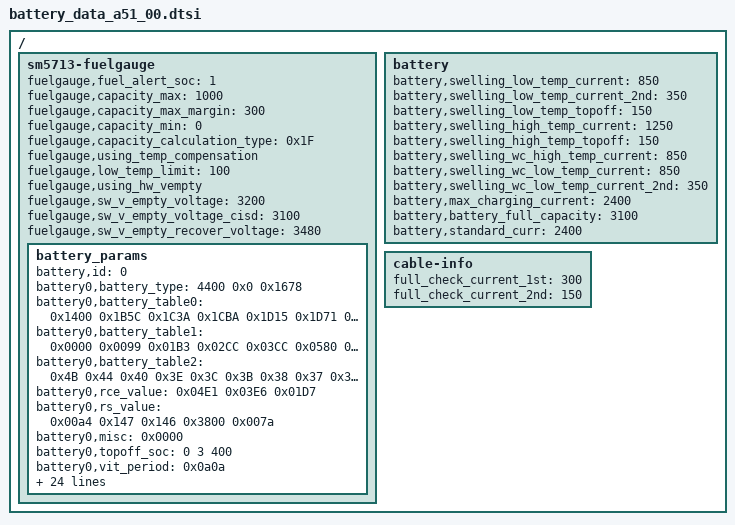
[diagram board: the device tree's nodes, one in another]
/*
 * Vogue battery device tree common
 *
 * Copyright (c) 2018 Samsung Electronics Co., Ltd.
 *		http://www.samsung.com
 *
 * This program is free software; you can redistribute it and/or modify
 * it under the terms of the GNU General Public License version 2 as
 * published by the Free Software Foundation.
 */

#include "battery_data_a51_common.dtsi"

/ {
	fragment@battery {
		target-path = "/";
		__overlay__ {
			sm5713-fuelgauge {
				status = "okay";
				fuelgauge,fuel_alert_soc = <1>;
				fuelgauge,capacity_max = <1000>;
				fuelgauge,capacity_max_margin = <300>;
				fuelgauge,capacity_min = <0>;
				fuelgauge,capacity_calculation_type = <0x1F>;
				fuelgauge,using_temp_compensation;
				fuelgauge,low_temp_limit = <100>;
				fuelgauge,using_hw_vempty;
				fuelgauge,sw_v_empty_voltage = <3200>;
				fuelgauge,sw_v_empty_voltage_cisd = <3100>;
				fuelgauge,sw_v_empty_recover_voltage = <3480>;
				battery_params {
					battery,id = <0>;
					battery0,battery_type = <4400 0x0 0x1678>; /* batt_v_max, min_cap, cap */
					battery0,battery_table0 = <
						0x1400 0x1B5C 0x1C3A 0x1CBA 0x1D15 0x1D71 0x1D85 0x1D8B
						0x1DE2 0x1E07 0x1E3A 0x1E5D 0x1E7B 0x1EA2 0x1ED6 0x1EFD
						0x1F69 0x1FB2 0x1FDF 0x2018 0x2078 0x20C3 0x21F2 0x2400
						>;
					battery0,battery_table1 = <
						0x0000 0x0099 0x01B3 0x02CC 0x03CC 0x0580 0x0819 0x0ACC
						0x12CC 0x1819 0x2033 0x2833 0x2D80 0x32E6 0x3833 0x3AE6
						0x4033 0x4599 0x4AE6 0x4D99 0x5033 0x5599 0x6400 0x6419
						>;
					battery0,battery_table2 = <
						0x4B 0x44 0x40 0x3E 0x3C 0x3B 0x38 0x37
						0x35 0x34 0x34 0x33 0x33 0x33 0x33 0x32
						>;
					battery0,rce_value = <0x04E1 0x03E6 0x01D7>;
					battery0,rs_value = <0x00a4 0x147 0x146 0x3800 0x007a>; /*rs p_mix_factor, n_mix_factor max min*/
					battery0,misc = <0x0000>;
					battery0,topoff_soc = <0 3 400>; /*disable soc*/
					battery0,vit_period = <0x0a0a>;
					battery0,dtcd_value = <0x1>;
					battery0,volt_cal = <0x8012 0x8012>;
					battery0,curr_offset = <1 0 0 0 0 0 0>;
					battery0,mix_value = <0x0103 0x0004>; /*mix_rate init_blank*/
					battery0,temp_std = <25>;
					battery0,temp_cal = <0 6 1 11 (-1) 1 6 1 9 1>;
					battery0,ext_temp_cal = <0 2 1 2 1 1 2 3 2 3>;
					battery0,temp_volcal = <1 15 1>;
					battery0,temp_offset = <1 11 1 1 8 (-1)>;
					battery0,curr_cal = <0x887D 0x887D 0x887D 0x8080 0x8080 0x8080>;
					battery0,tem_poff = <3400 50 3250 50>;
					battery0,arsm = <1 3 1 0x6>;
					battery0,cycle_cfg = <0 0 0>;
					battery0,full_offset = <0 50 0 0xD1 0x90>;
					battery0,age_cntl = <0x325>;
					battery0,tcal_ioff = <0x02 0x30>;
					battery0,v_offset_cancel = <0 0 100 10>;
					battery0,v_alarm = <3100 0>;
					battery0,data_ver = <1>;
					battery0,v_max_table = <0x21F2 0x21CF 0x21AC 0x2189 0x2140>;
					battery0,q_max_table = <0x1678 0x15F8 0x1578 0x14F8 0x13CC>;
				};
			};

			battery {
				battery,swelling_low_temp_current = <850>;	/* 0.3C */
				battery,swelling_low_temp_current_2nd = <350>;	/* 0.1C */
				battery,swelling_low_temp_topoff = <150>;	/* 0.05C */
				battery,swelling_high_temp_current = <1250>;	/* 0.45C */
				battery,swelling_high_temp_topoff = <150>;	/* 0.05C */
				battery,swelling_wc_high_temp_current = <850>;	/* 0.3C */
				battery,swelling_wc_low_temp_current = <850>;	/* 0.3C */
				battery,swelling_wc_low_temp_current_2nd = <350>;	/* 0.3C */

				battery,max_charging_current = <2400>;
				battery,battery_full_capacity = <3100>;

				battery,standard_curr = <2400>;
			};

		/* sec_battery_cable
		 *   0	UNKNOWN,
		 *   1	NONE,
		 *   2	PREPARE_TA,
		 *   3	TA,
		 *   4	USB,
		 *   5	USB_CDP,
		 *   6	9V_TA,
		 *   7	9V_ERR,
		 *   8	9V_UNKNOWN,
		 *   9	12V_TA,
		 *  10	WIRELESS,
		 *  11	HV_WIRELESS,
		 *  12	PMA_WIRELESS,
		 *  13	WIRELESS_PACK,
		 *  14	WIRELESS_PACK_TA,
		 *  15	WIRELESS_STAND,
		 *  16	WIRELESS_HV_STAND,
		 *  17	QC20,
		 *  18	QC30,
		 *  19	PDIC,
		 *  20	UARTOFF,
		 *  21	OTG,
		 *  22	LAN_HUB,
		 *  23	POWER_SHARING,
		 *  24	HMT_CONNECTED,
		 *  25	HMT_CHARGE,
		 *  26	HV_TA_CHG_LIMIT,
		 *  27	WIRELESS_VEHICLE,
		 *  28	WIRELESS_HV_VEHICLE,
		 *  29	PREPARE_WIRELESS_HV,
		 *  30	TIMEOUT,
		 *  31	SMART_OTG,
		 *  32	SMART_NOTG,
		 *  33	CABLE_MAX,
		 */
			cable-info {
				full_check_current_1st = <300>;
				full_check_current_2nd = <150>;
			};
		};
	};
};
